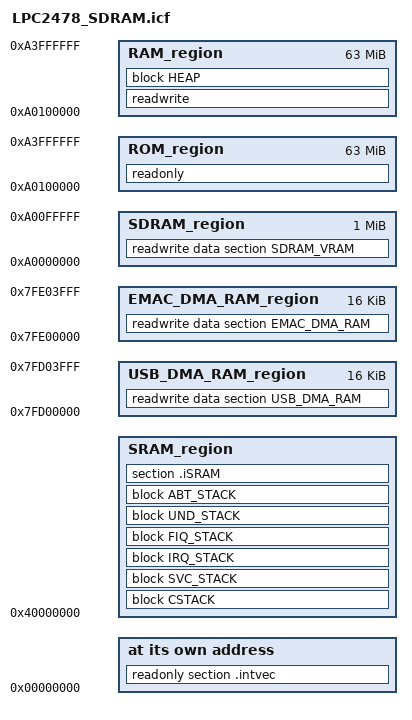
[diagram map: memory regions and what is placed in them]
/*###ICF### Section handled by ICF editor, don't touch! ****/
/*-Editor annotation file-*/
/* IcfEditorFile="$TOOLKIT_DIR$\config\ide\IcfEditor\a_v1_0.xml" */
/*-Specials-*/
define symbol __ICFEDIT_intvec_start__              = 0x00000000;
/*-Memory Regions-*/
define symbol __ICFEDIT_region_ROM_start__          = 0xA0100000;
define symbol __ICFEDIT_region_ROM_end__            = 0xA3FFFFFF;
define symbol __ICFEDIT_region_RAM_start__          = 0xA0100000;
define symbol __ICFEDIT_region_RAM_end__            = 0xA3FFFFFF;
/*-Sizes-*/
define symbol __ICFEDIT_size_cstack__   = 0x400;
define symbol __ICFEDIT_size_svcstack__ = 0x100;
define symbol __ICFEDIT_size_irqstack__ = 0x400;
define symbol __ICFEDIT_size_fiqstack__ = 0x40;
define symbol __ICFEDIT_size_undstack__ = 0x10;
define symbol __ICFEDIT_size_abtstack__ = 0x10;
define symbol __ICFEDIT_size_heap__     = 0x2000;
/**** End of ICF editor section. ###ICF###*/

define memory mem with size = 4G;
define region ROM_region        = mem:[from __ICFEDIT_region_ROM_start__            to __ICFEDIT_region_ROM_end__];
define region RAM_region        = mem:[from __ICFEDIT_region_RAM_start__            to __ICFEDIT_region_RAM_end__];

define symbol __region_USB_DMA_RAM_start__  = 0x7FD00000;
define symbol __region_USB_DMA_RAM_end__    = 0x7FD03FFF;
define region USB_DMA_RAM_region= mem:[from __region_USB_DMA_RAM_start__    to __region_USB_DMA_RAM_end__];

define symbol __region_EMAC_DMA_RAM_start__ = 0x7FE00000;
define symbol __region_EMAC_DMA_RAM_end__   = 0x7FE03FFF;
define region EMAC_DMA_RAM_region= mem:[from __region_EMAC_DMA_RAM_start__  to __region_EMAC_DMA_RAM_end__];

define symbol __region_SDRAM_VRAM__start__ = 0xA0000000;
define symbol __region_SDRAM_VRAM_end__    = 0xA00FFFFF;
define region SDRAM_region= mem:[from __region_SDRAM_VRAM__start__  to __region_SDRAM_VRAM_end__];

define symbol __region_SRAM_start__        = 0x40000000;
define symbol __region_SRAM_end__          = 0x4000FFDF;

/* Memory used by RealMonitor*/
define symbol __RM_start__   = 0x40000040;
define symbol __RM_end__     = 0x4000011F;

define region SRAM_region= mem:[from __region_SRAM_start__  to __region_SRAM_end__] - mem:[from  __RM_start__ to __RM_end__];

define block CSTACK    with alignment = 8, size = __ICFEDIT_size_cstack__   { };
define block SVC_STACK with alignment = 8, size = __ICFEDIT_size_svcstack__ { };
define block IRQ_STACK with alignment = 8, size = __ICFEDIT_size_irqstack__ { };
define block FIQ_STACK with alignment = 8, size = __ICFEDIT_size_fiqstack__ { };
define block UND_STACK with alignment = 8, size = __ICFEDIT_size_undstack__ { };
define block ABT_STACK with alignment = 8, size = __ICFEDIT_size_abtstack__ { };
define block HEAP      with alignment = 8, size = __ICFEDIT_size_heap__     { };

initialize by copy { readwrite };
do not initialize  { section .noinit };
do not initialize  { section USB_DMA_RAM };
do not initialize  { section EMAC_DMA_RAM };

place at address mem:__ICFEDIT_intvec_start__ { readonly section .intvec };

place in ROM_region   { readonly };
place in RAM_region   { readwrite,
                        block HEAP };
place in SRAM_region  { block CSTACK, block SVC_STACK, block IRQ_STACK, block FIQ_STACK,
                        block UND_STACK, block ABT_STACK, section .iSRAM};
place in USB_DMA_RAM_region
                      { readwrite data section USB_DMA_RAM };
place in EMAC_DMA_RAM_region
                      { readwrite data section EMAC_DMA_RAM };
place in SDRAM_region { readwrite data section SDRAM_VRAM };
define exported symbol SDRAM_BASE_ADDR = __region_SDRAM_VRAM__start__;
